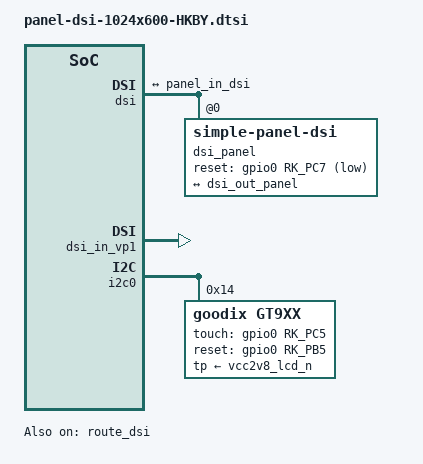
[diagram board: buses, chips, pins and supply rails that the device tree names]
#include <dt-bindings/display/drm_mipi_dsi.h>

/ {
	backlight: backlight {
		compatible = "pwm-backlight";
		status = "disabled";
		pwms = <&pwm1_6ch_1 0 25000 0>;
		brightness-levels = <
			  0  20  20  21  21  22  22  23
			 23  24  24  25  25  26  26  27
			 27  28  28  29  29  30  30  31
			 31  32  32  33  33  34  34  35
			 35  36  36  37  37  38  38  39
			 40  41  42  43  44  45  46  47
			 48  49  50  51  52  53  54  55
			 56  57  58  59  60  61  62  63
			 64  65  66  67  68  69  70  71
			 72  73  74  75  76  77  78  79
			 80  81  82  83  84  85  86  87
			 88  89  90  91  92  93  94  95
			 96  97  98  99 100 101 102 103
			104 105 106 107 108 109 110 111
			112 113 114 115 116 117 118 119
			120 121 122 123 124 125 126 127
			128 129 130 131 132 133 134 135
			136 137 138 139 140 141 142 143
			144 145 146 147 148 149 150 151
			152 153 154 155 156 157 158 159
			160 161 162 163 164 165 166 167
			168 169 170 171 172 173 174 175
			176 177 178 179 180 181 182 183
			184 185 186 187 188 189 190 191
			192 193 194 195 196 197 198 199
			200 201 202 203 204 205 206 207
			208 209 210 211 212 213 214 215
			216 217 218 219 220 221 222 223
			224 225 226 227 228 229 230 231
			232 233 234 235 236 237 238 239
			240 241 242 243 244 245 246 247
			248 249 250 251 252 253 254 255
		>;
		default-brightness-level = <200>;
		//enable-gpios = <&gpio2 RK_PC3 GPIO_ACTIVE_HIGH>;
	};
};

&pwm1_6ch_1 {
       status = "disabled";
};

&dsi {
	status = "okay";
	//auto-calculation-mode;
	//rockchip,lane-rate = <800>;
	dsi_panel: panel@0 {
		status = "okay";
		compatible = "simple-panel-dsi";
		reg = <0>;
		//backlight = <&backlight>;
		//enable-gpios = <&gpio0 RK_PC6 GPIO_ACTIVE_HIGH>;
		reset-gpios = <&gpio0 RK_PC7 GPIO_ACTIVE_LOW>;

		pinctrl-names = "default";
		pinctrl-0 = <&lcd_enable_gpio>, <&lcd_rst_gpio>;

		prepare-delay-ms = <40>;
		reset-delay-ms = <60>;
		init-delay-ms = <80>;
		stbyb-delay-ms = <20>;
		enable-delay-ms = <60>;
		disable-delay-ms = <20>;
		unprepare-delay-ms = <20>;
		width-mm = <135>;
		height-mm = <216>;
		dsi,flags = <(MIPI_DSI_MODE_VIDEO | MIPI_DSI_MODE_VIDEO_BURST |
			      MIPI_DSI_MODE_LPM | MIPI_DSI_MODE_NO_EOT_PACKET | MIPI_DSI_CLOCK_NON_CONTINUOUS)>;
		dsi,format = <MIPI_DSI_FMT_RGB888>;
		dsi,lanes  = <4>;
		panel-init-sequence = [
15 00 02 30 00 
39 00 05 F7 49 61 02 00 
15 00 02 30 01 
15 00 02 04 0C 
15 00 02 05 08 
15 00 02 0B 10 
15 00 02 1F 05   //mipi_hs_settle  //0x05->0x00 (P7_r01=04)
15 00 02 23 38 
15 00 02 28 18 
15 00 02 29 29 
15 00 02 2A 01 
15 00 02 2B 29 
15 00 02 2C 01 
15 00 02 30 02 
15 00 02 00 05 
15 00 02 01 22 
15 00 02 02 08 
15 00 02 03 12 
15 00 02 04 16 
15 00 02 05 64 
15 00 02 06 00 
15 00 02 07 00 
15 00 02 08 78 
15 00 02 09 00 
15 00 02 0A 04 
39 00 0C 0B 16 17 0B 0D 0D 0D 11 10 07 07 09 
39 00 0C 0C 09 1E 1E 1C 1C 0D 0D 0D 0D 0D 0D 
39 00 0C 0D 0A 05 0B 0D 0D 0D 11 10 06 06 08 
39 00 0C 0E 08 1F 1F 1D 1D 0D 0D 0D 0D 0D 0D 
39 00 0C 0F 0A 05 0D 0B 0D 0D 11 10 1D 1D 1F 
39 00 0C 10 1F 08 08 06 06 0D 0D 0D 0D 0D 0D 
39 00 0C 11 16 17 0D 0B 0D 0D 11 10 1C 1C 1E 
39 00 0C 12 1E 09 09 07 07 0D 0D 0D 0D 0D 0D 
39 00 05 13 00 00 00 00 
39 00 05 14 00 00 41 41 
39 00 05 15 00 00 00 00 
15 00 02 17 00 
15 00 02 18 85 
39 00 03 19 06 09 
39 00 03 1A 05 08 
39 00 03 1B 0A 04 
15 00 02 26 00 
15 00 02 27 00 
15 00 02 30 06 
39 00 0F 12 3F 25 27 35 1D 1B 1B 1A 18 0A 2A 21 19 30 
39 00 0F 13 3F 26 27 35 1E 1C 1C 1A 18 0B 2A 21 19 30 
15 00 02 30 0A 
15 00 02 02 4F 
15 00 02 0B 40 
15 00 02 30 0D 
15 00 02 0D 04  //mipi add  //0x0C, 0x04
15 00 02 10 05 
15 00 02 11 0C 
15 00 02 12 05 
15 00 02 13 0C 
15 00 02 30 00 
		       05 78 01 11        
		       05 64 01 29 
		];

		panel-exit-sequence = [
			05 10 01 28
			05 78 01 10
		];

		disp_timings0: display-timings {
			native-mode = <&dsi_timing0>;
			dsi_timing0: timing0 {
				clock-frequency = <50000000>;                                               
				hactive = <1024>;                                                            
				vactive = <600>;                                                            
				hback-porch = <136>;                                                          
				hfront-porch = <160>;                                                         
				vback-porch = <21>;                                                          
				vfront-porch = <12>;                                                         
				hsync-len = <24>;                                                            
				vsync-len = <2>;                                                             
				hsync-active = <0>;                                                          
				vsync-active = <0>;                                                          
				de-active = <0>;                                                             
				pixelclk-active = <0>;
			};
		};

		ports {
			#address-cells = <1>;
			#size-cells = <0>;

			port@0 {
				reg = <0>;
				panel_in_dsi: endpoint {
					remote-endpoint = <&dsi_out_panel>;
				};
			};
		};
	};

	ports {
		#address-cells = <1>;
		#size-cells = <0>;

		port@1 {
			reg = <1>;
			dsi_out_panel: endpoint {
				remote-endpoint = <&panel_in_dsi>;
			};
		};
	};
};

&dsi_in_vp1 {
	status = "okay";
};

&route_dsi {
	status = "okay";
};



&i2c0 {
        status = "okay";
        pinctrl-names = "default";
        pinctrl-0 = <&i2c0m1_xfer>;

        gt9xx: gt9xx@14 {
                compatible = "goodix,gt9xx";
                reg = <0x14>;
                pinctrl-names = "default";
                pinctrl-0 = <&touch_gpio>;
                touch-gpio = <&gpio0 RK_PC5 IRQ_TYPE_LEVEL_HIGH>;
                reset-gpio = <&gpio0 RK_PB5 GPIO_ACTIVE_HIGH>;
                max-x = <1200>;
                max-y = <1920>;
                tp-size = <9110>;
				tp-supply = <&vcc2v8_lcd_n>;
        };
};
